# PIC32CX5109BZ31048 register map
Vendor: Microchip Technology; Series: PIC32CXBZ31; File version: 0
CPU: CM4 r0p1, little endian, MPU, FPU, 3 interrupt priority bits, 43 interrupts
Registers are 32-bit, read-write, reset 0x0 unless marked. A register's access mark holds for its fields unless they carry their own. Offsets are from the block's base; [hi:lo] are bit positions.

## DGI_SPI — SPI DMA for DGI Macro
Base 0x44003E00
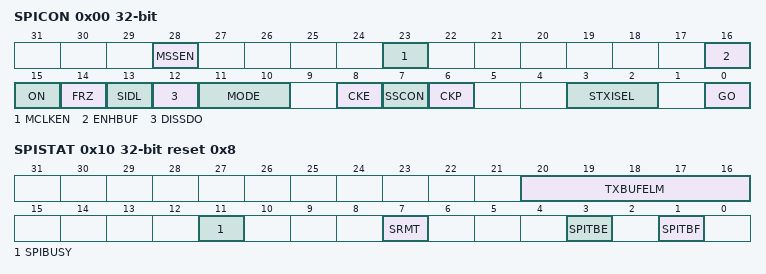
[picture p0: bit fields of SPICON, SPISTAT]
0x00 SPICON — SPI control register
  [28] MSSEN — Master Mode Slave Select Enable bit
    0=Slave select SPI support disabled; 1=SPI Slave Select support enabled
  [23] MCLKEN — Master Clock Enable
    0=PBCLK is used by the BRG; 1=MCLK is used by the BRG
  [16] ENHBUF — Enhanced Buffer Enable bit
    0=Enhanced Buffer Mode is disabled; 1=Enhanced Buffer Mode is enabled
  [15] ON — DGISPI On bit
    0=Turn off and reset macro, disable clocks, disable interrupt event generation, allow SFR modifications; 1=Enable macro
  [14] FRZ — Freeze bit (in Debug Mode)
    0=Continue macro operation when in Debug mode; 1=Break macro operation when in Debug mode
  [13] SIDL — Stop in Idle control bit
    0=Continue to operate in CPU Idle mode; 1=Halt in CPU Idle mode
  [12] DISSDO — Disable SDO bit
    0=SDO pin is controlled by the macro; 1=SDO pin is not used by the macro. Pin controlled by PORT function
  [11:10] MODE — Serial Word Length bits
  [8] CKE — SPI Clock Edge Select bit
    0=Transmit happens on transition from idle clock state to active clock stat e; 1=Transmit happens on transition from active clock state to idle clock state
  [7] SSCON — SSControl bits
    0=SS is not controlled by the DMA module; 1=SS is asserted for the duration of TXCNT
  [6] CKP — Clock Polarity Select bit
    0=Idle state for clock is a low level; active state is a high level; 1=Idle state for clock is a high level; active state is a low level
  [3:2] STXISEL — SPI Transmit Service Request Interrupt SelectFor enhanced buffer mode, the SPI generates a Transmit Service Request when:
    0=The SPIxTXB is empty and SPIxSR is empty (i.e. all transmit operations are complete); 1=The SPIxTXB is empty; 2=The SPIxTXB is at least half empty; 3=The SPIxTXB is not full
  [0] GO — DMA Operation Status bitThis bit is set by the user software to start the DMA operation. It is reset back to zero by the DMA engine whenthe DMA operation is completed or aborted by clearing the ON bit.
    0=DMA is not in operation; 1=DMA is in operation
0x10 SPISTAT ro reset 0x8 — SPI Status register
  [20:16] TXBUFELM — TransmitBuffer Element Count bits (valid only when ENHBUF = 1)
  [11] SPIBUSY — SPI activity status bit
    0=No on-going transactions (at time of read); 1=Macro currently busy with some transactions
  [7] SRMT — Shift Register (SPIxSR) Empty bit0= There are current or pending transactions
    1=There are no current or pending transactions
  [3] SPITBE — SPI Transmit Buffer Empty status bit
    0=SPIxTXB is not empty; 1=SPIxTXB is empty
  [1] SPITBF — SPI Transmit Buffer Full Status bit
    0=SPIxTXB not full; 1=SPIxTXB is full
0x20 SPIBUF — SPI BUFFER register
  [31:0] DATA — FIFO Data bits
0x30 SPIBRG — SPI Baud rate register
  [12:0] BRG — Baud Rate Divisor bitsseeSection 2.4.1.
0x40 SPITXADD — SPI DMA Transmit Address register
  [15:0] TXADD — Transmit Source Address bitsTXADD can constantly be updated to reflect the current transmit address as the transfer progresses
0x50 SPITXCNT — SPI DMA Transmit Count register
  [15:0] TXCNT — Transmit Count bitsThis register indicates the number of transferred data words. As the DMA progresses, TXCNT is constantly decremented to reflect the remaining count yet to be transferred.

## DMT — Dead Man Timer
Base 0x44000E00
0x00 DMTCON
  [15] ON
0x04 DMTCONCLR — Bit clear register
0x08 DMTCONSET — Bit set register
0x0C DMTCONINV — Bit invert register
0x10 DMTPRECLR
  [15:8] STEP1
0x14 DMTPRECLRCLR — Bit clear register
0x18 DMTPRECLRSET — Bit set register
0x1C DMTPRECLRINV — Bit invert register
0x20 DMTCLR
  [7:0] STEP2
0x24 DMTCLRCLR — Bit clear register
0x28 DMTCLRSET — Bit set register
0x2C DMTCLRINV — Bit invert register
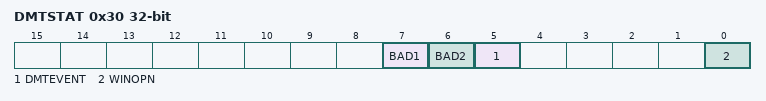
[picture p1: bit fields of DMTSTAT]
0x30 DMTSTAT
  [7] BAD1, [6] BAD2, [5] DMTEVENT, [0] WINOPN
0x34 DMTSTATCLR — Bit clear register
0x38 DMTSTATSET — Bit set register
0x3C DMTSTATINV — Bit invert register
0x40 DMTCNT ro
  [31:0] COUNTER
0x44 DMTCNTCLR — Bit clear register
0x48 DMTCNTSET — Bit set register
0x4C DMTCNTINV — Bit invert register
0x50 DMTHOLDREG ro
  [15:0] UPRCNT
0x54 DMTHOLDREGCLR — Bit clear register
0x58 DMTHOLDREGSET — Bit set register
0x5C DMTHOLDREGINV — Bit invert register
0x60 DMTPSCNT ro
  [31:0] PSCNT
0x64 DMTPSCNTCLR — Bit clear register
0x68 DMTPSCNTSET — Bit set register
0x6C DMTPSCNTINV — Bit invert register
0x70 DMTPSINTV ro
  [31:0] PSINTV
0x74 DMTPSINTVCLR — Bit clear register
0x78 DMTPSINTVSET — Bit set register
0x7C DMTPSINTVINV — Bit invert register
